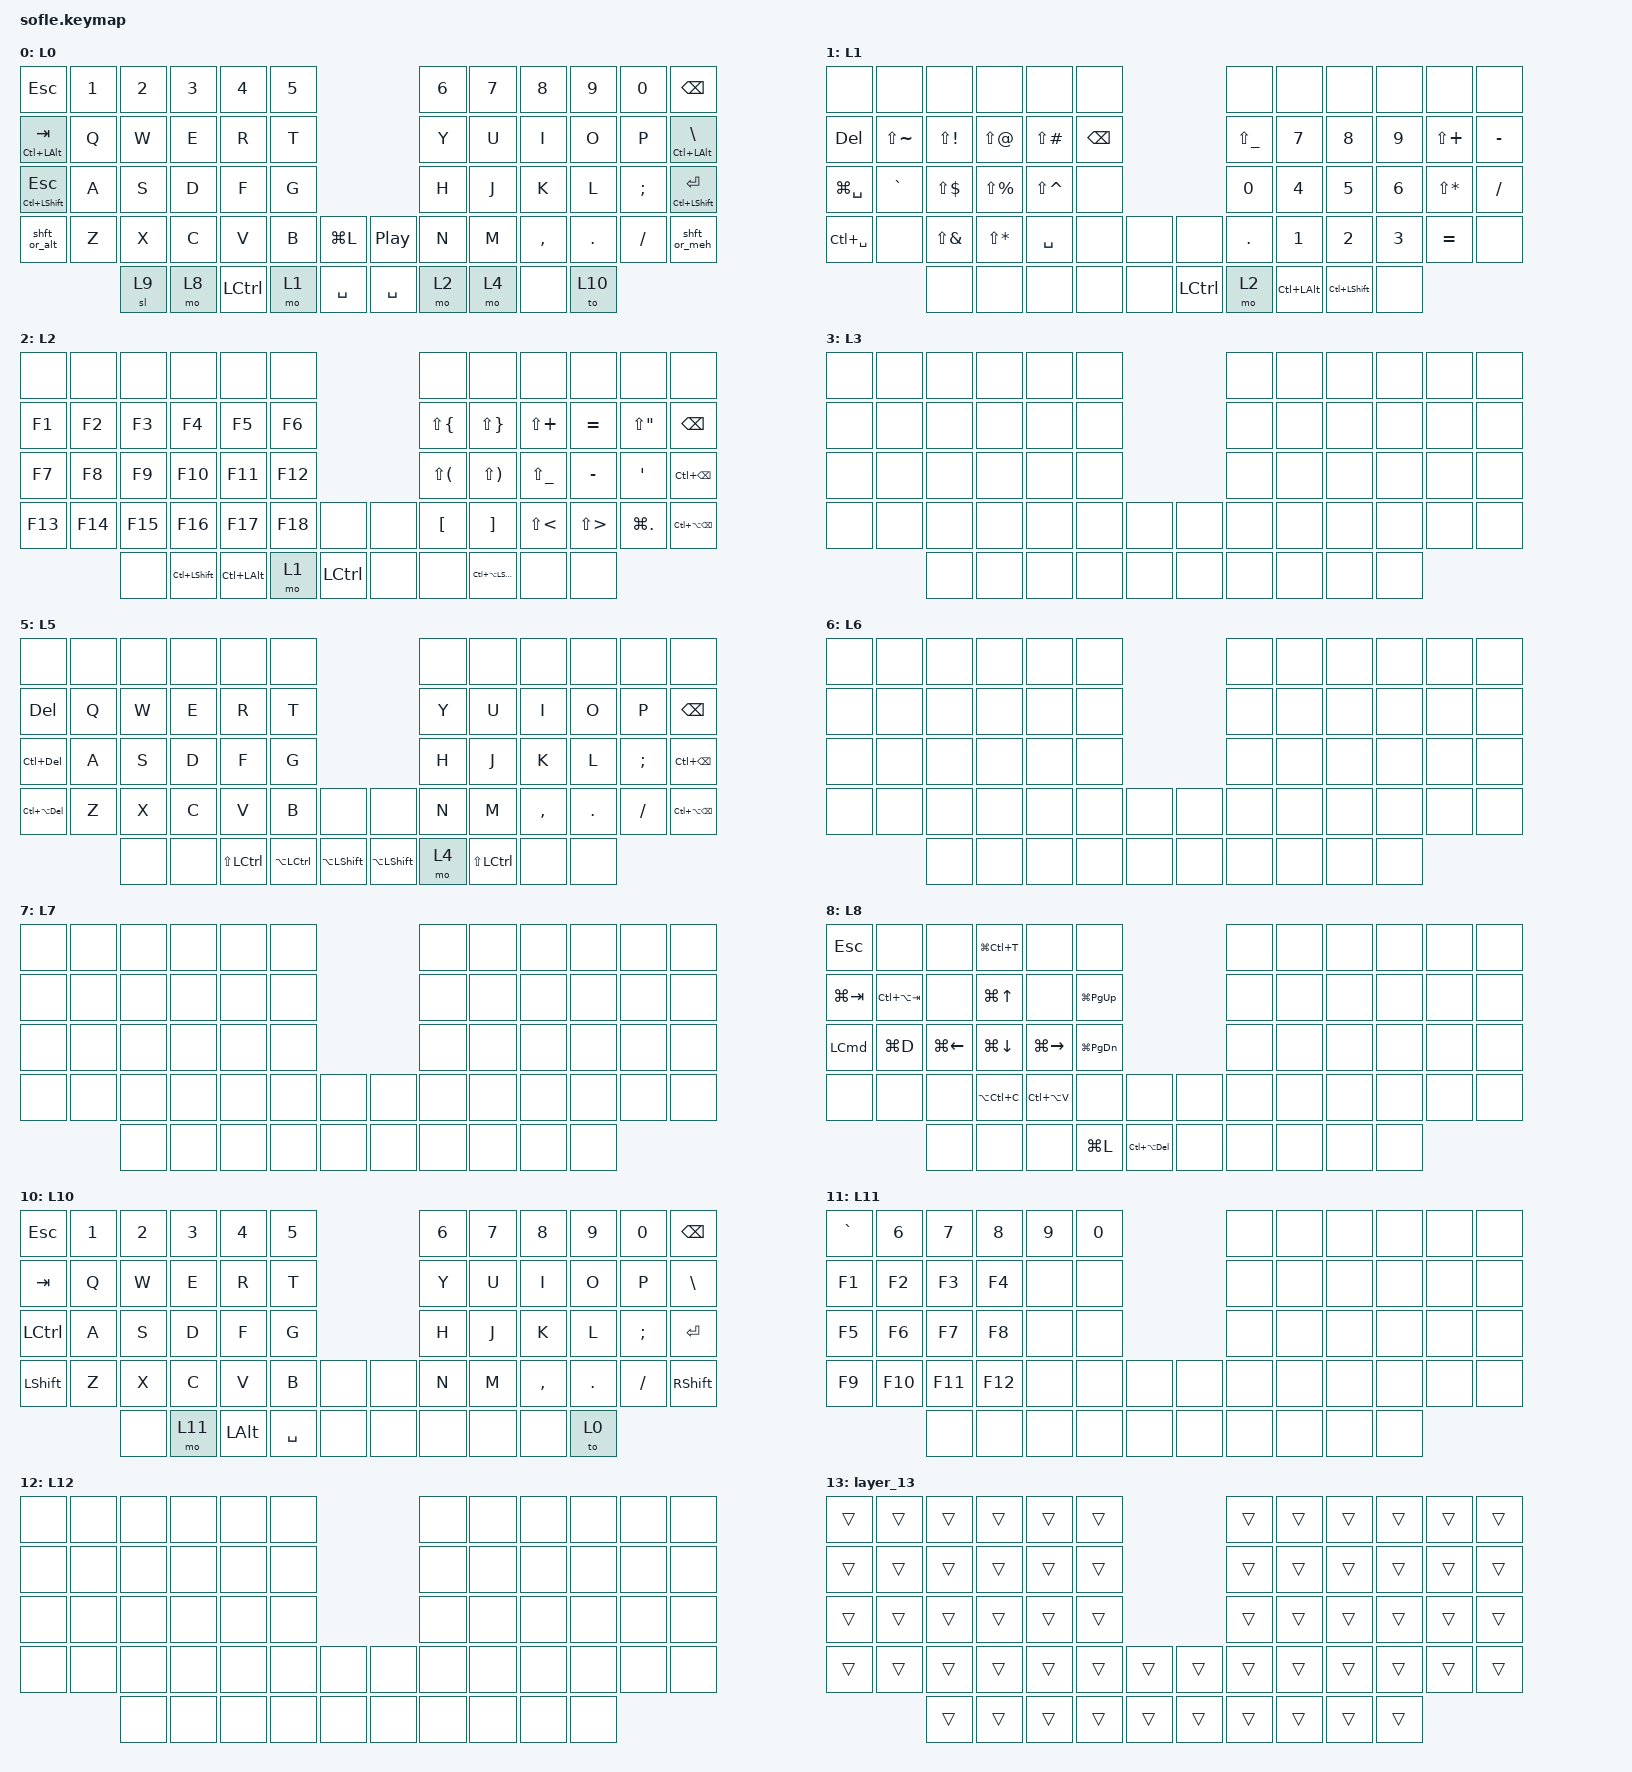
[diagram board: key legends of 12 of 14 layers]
/*
 * Copyright (c) 2020 The ZMK Contributors
 *
 * SPDX-License-Identifier: MIT
 */

#include <behaviors.dtsi>
#include <dt-bindings/zmk/bt.h>
#include <dt-bindings/zmk/ext_power.h>
#include <dt-bindings/zmk/keys.h>
#include <dt-bindings/zmk/outputs.h>

#define L0 0
#define L1 1
#define L2 2
#define L3 3
#define L4 4
#define L5 5
#define L6 6
#define L7 7
#define L8 8
#define L9 9
#define L10 10
#define L11 11
#define L12 12

/ {
    // Activate ADJUST layer by pressing raise and lower

    conditional_layers {
        compatible = "zmk,conditional-layers";

        combined_layer_1 {
            if-layers = <1 2>;
            then-layer = <3>;
        };

        combined_layer_2 {
            if-layers = <4 5>;
            then-layer = <6>;
        };
    };

    behaviors {
        shft_or_alt: shft_or_alt {
            compatible = "zmk,behavior-tap-dance";
            label = "SHFT_OR_ALT";
            #binding-cells = <0>;
            bindings = <&kp LSHFT>, <&kp LEFT_ALT>;
        };
        shft_or_meh: shft_or_meh {
            compatible = "zmk,behavior-tap-dance";
            label = "SHFT_OR_MEH";
            #binding-cells = <0>;
            bindings = <&kp LSHFT>, <&kp LC(LA(LEFT_SHIFT))>;
        };
    };

    keymap {
        compatible = "zmk,keymap";

        L0 {
            bindings = <
&kp ESC                 &kp NUMBER_1  &kp N2  &kp N3  &kp N4     &kp N5                        &kp N6  &kp N7  &kp N8     &kp N9   &kp N0    &kp BACKSPACE
&mt LC(LALT) TAB        &kp Q         &kp W   &kp E   &kp R      &kp T                         &kp Y   &kp U   &kp I      &kp O    &kp P     &mt LC(LEFT_ALT) BACKSLASH
&mt LC(LEFT_SHIFT) ESC  &kp A         &kp S   &kp D   &kp F      &kp G                         &kp H   &kp J   &kp K      &kp L    &kp SEMI  &mt LC(LSHFT) ENTER
&shft_or_alt            &kp Z         &kp X   &kp C   &kp V      &kp B   &kp LG(L)  &kp C_PP   &kp N   &kp M   &kp COMMA  &kp DOT  &kp FSLH  &shft_or_meh
                                      &sl 9   &mo 8   &kp LCTRL  &mo 1   &kp SPACE  &kp SPACE  &mo 2   &mo 4   &none      &to 10
            >;

            sensor-bindings =
                <&inc_dec_kp C_VOL_UP C_VOL_DN>,
                <&inc_dec_kp C_NEXT C_PREV>;
        };

        L1 {
            bindings = <
&none          &none          &none         &none          &none          &none                       &none          &none             &none               &none   &none         &none
&kp DEL        &kp LS(TILDE)  &kp LS(EXCL)  &kp LS(AT)     &kp LS(POUND)  &kp BSPC                    &kp LS(UNDER)  &kp N7            &kp N8              &kp N9  &kp LS(PLUS)  &kp MINUS
&kp LG(SPACE)  &kp GRAVE      &kp LS(DLLR)  &kp LS(PRCNT)  &kp LS(CARET)  &none                       &kp N0         &kp N4            &kp N5              &kp N6  &kp LS(STAR)  &kp FSLH
&kp LC(SPACE)  &none          &kp LS(AMPS)  &kp LS(STAR)   &kp SPACE      &none     &none  &none      &kp DOT        &kp N1            &kp N2              &kp N3  &kp EQUAL     &none
                              &none         &none          &none          &none     &none  &kp LCTRL  &mo 2          &kp LC(LEFT_ALT)  &kp LC(LEFT_SHIFT)  &none
            >;
        };

        L2 {
            bindings = <
&none    &none    &none    &none               &none             &none                      &none         &none                   &none          &none       &none           &none
&kp F1   &kp F2   &kp F3   &kp F4              &kp F5            &kp F6                     &kp LS(LBRC)  &kp LS(RBRC)            &kp LS(PLUS)   &kp EQUAL   &kp LS(DQT)     &kp BSPC
&kp F7   &kp F8   &kp F9   &kp F10             &kp F11           &kp F12                    &kp LS(LPAR)  &kp LS(RPAR)            &kp LS(UNDER)  &kp MINUS   &kp SQT         &kp LC(BSPC)
&kp F13  &kp F14  &kp F15  &kp F16             &kp F17           &kp F18  &none      &none  &kp LBKT      &kp RBKT                &kp LS(LT)     &kp LS(GT)  &kp LG(PERIOD)  &kp LC(LA(BSPC))
                  &none    &kp LC(LEFT_SHIFT)  &kp LC(LEFT_ALT)  &mo 1    &kp LCTRL  &none  &none         &kp LC(LA(LEFT_SHIFT))  &none          &none
            >;
        };

        L3 {
            bindings = <
&none  &none  &none  &none  &none  &none                &none  &none  &none  &none  &none  &none
&none  &none  &none  &none  &none  &none                &none  &none  &none  &none  &none  &none
&none  &none  &none  &none  &none  &none                &none  &none  &none  &none  &none  &none
&none  &none  &none  &none  &none  &none  &none  &none  &none  &none  &none  &none  &none  &none
              &none  &none  &none  &none  &none  &none  &none  &none  &none  &none
            >;
        };

        L4 {
            bindings = <
&none         &none     &none             &none               &none              &none                    &none              &none              &none               &none               &none                  &none
&kp LC(HOME)  &kp HOME  &kp LC(LEFT)      &kp UP              &kp LC(RIGHT)      &kp PG_UP                &kp LS(LC(LA(Y)))  &kp LS(LC(LA(U)))  &kp LS(LC(LA(I)))   &kp LS(LC(LA(O)))   &kp LS(LC(LA(P)))      &kp LS(LC(LA(PIPE)))
&kp LC(END)   &kp END   &kp LEFT          &kp DOWN            &kp RIGHT          &kp PG_DN                &kp LS(LC(LA(H)))  &kp LS(LC(LA(J)))  &kp LS(LC(LA(K)))   &kp LS(LC(LA(L)))   &kp LS(LC(LA(COLON)))  &none
&none         &none     &kp LC(LA(LEFT))  &none               &kp LC(LA(RIGHT))  &none      &none  &none  &kp LS(LC(LA(N)))  &kp LS(LC(LA(M)))  &kp LS(LC(LA(LT)))  &kp LS(LC(LA(GT)))  &kp LS(LC(LA(QMARK)))  &none
                        &none             &kp LC(LEFT_SHIFT)  &kp LEFT_ALT       &kp LSHFT  &none  &none  &none              &none              &none               &none
            >;
        };

        L5 {
            bindings = <
&none            &none  &none  &none  &none          &none                                        &none  &none          &none      &none    &none     &none
&kp DEL          &kp Q  &kp W  &kp E  &kp R          &kp T                                        &kp Y  &kp U          &kp I      &kp O    &kp P     &kp BSPC
&kp LC(DEL)      &kp A  &kp S  &kp D  &kp F          &kp G                                        &kp H  &kp J          &kp K      &kp L    &kp SEMI  &kp LC(BSPC)
&kp LC(LA(DEL))  &kp Z  &kp X  &kp C  &kp V          &kp B          &none          &none          &kp N  &kp M          &kp COMMA  &kp DOT  &kp FSLH  &kp LC(LA(BSPC))
                        &none  &none  &kp LS(LCTRL)  &kp LA(LCTRL)  &kp LA(LSHFT)  &kp LA(LSHFT)  &mo 4  &kp LS(LCTRL)  &none      &none
            >;
        };

        L6 {
            bindings = <
&none  &none  &none  &none  &none  &none                &none  &none  &none  &none  &none  &none
&none  &none  &none  &none  &none  &none                &none  &none  &none  &none  &none  &none
&none  &none  &none  &none  &none  &none                &none  &none  &none  &none  &none  &none
&none  &none  &none  &none  &none  &none  &none  &none  &none  &none  &none  &none  &none  &none
              &none  &none  &none  &none  &none  &none  &none  &none  &none  &none
            >;
        };

        L7 {
            bindings = <
&none  &none  &none  &none  &none  &none                &none  &none  &none  &none  &none  &none
&none  &none  &none  &none  &none  &none                &none  &none  &none  &none  &none  &none
&none  &none  &none  &none  &none  &none                &none  &none  &none  &none  &none  &none
&none  &none  &none  &none  &none  &none  &none  &none  &none  &none  &none  &none  &none  &none
              &none  &none  &none  &none  &none  &none  &none  &none  &none  &none
            >;
        };

        L8 {
            bindings = <
&kp ESC      &none            &none               &kp LG(LC(T))  &none          &none                                  &none  &none  &none  &none  &none  &none
&kp LG(TAB)  &kp LC(LA(TAB))  &none               &kp LG(UP)     &none          &kp LG(PG_UP)                          &none  &none  &none  &none  &none  &none
&kp LCMD     &kp LG(D)        &kp LG(LEFT_ARROW)  &kp LG(DOWN)   &kp LG(RIGHT)  &kp LG(PG_DN)                          &none  &none  &none  &none  &none  &none
&none        &none            &none               &kp LA(LC(C))  &kp LC(LA(V))  &none          &none            &none  &none  &none  &none  &none  &none  &none
                              &none               &none          &none          &kp LG(L)      &kp LC(LA(DEL))  &none  &none  &none  &none  &none
            >;
        };

        L9 {
            bindings = <
&kp ESC              &none                &none                &none                &none                &none                              &none  &none  &none  &none         &none         &ext_power EP_TOG
&kp LS(LA(LC(F1)))   &kp LS(LA(LC(F2)))   &kp LS(LA(LC(F3)))   &kp LS(LA(LC(F4)))   &kp LS(LA(LC(F5)))   &kp LS(LA(LC(F6)))                 &none  &none  &none  &none         &none         &bt BT_CLR
&kp LS(LA(LC(F7)))   &kp LS(LA(LC(F8)))   &kp LS(LA(LC(F9)))   &kp LS(LA(LC(F10)))  &kp LS(LA(LC(F11)))  &kp LS(LA(LC(F12)))                &none  &none  &none  &none         &out OUT_USB  &out OUT_BLE
&kp LS(LA(LC(F13)))  &kp LS(LA(LC(F14)))  &kp LS(LA(LC(F15)))  &kp LS(LA(LC(F16)))  &kp LS(LA(LC(F17)))  &kp LS(LA(LC(F18)))  &none  &none  &none  &none  &none  &bt BT_SEL 0  &bt BT_SEL 1  &bt BT_SEL 2
                                          &none                &none                &none                &none                &none  &none  &none  &none  &none  &to 10
            >;
        };

        L10 {
            bindings = <
&kp ESC    &kp N1  &kp N2  &kp N3  &kp N4        &kp N5                   &kp N6  &kp N7  &kp N8     &kp N9   &kp N0    &kp BSPC
&kp TAB    &kp Q   &kp W   &kp E   &kp R         &kp T                    &kp Y   &kp U   &kp I      &kp O    &kp P     &kp BSLH
&kp LCTRL  &kp A   &kp S   &kp D   &kp F         &kp G                    &kp H   &kp J   &kp K      &kp L    &kp SEMI  &kp RET
&kp LSHFT  &kp Z   &kp X   &kp C   &kp V         &kp B      &none  &none  &kp N   &kp M   &kp COMMA  &kp DOT  &kp FSLH  &kp RSHFT
                   &none   &mo 11  &kp LEFT_ALT  &kp SPACE  &none  &none  &none   &none   &none      &to 0
            >;
        };

        L11 {
            bindings = <
&kp GRAVE  &kp N6   &kp N7   &kp N8   &kp N9  &kp N0                &none  &none  &none  &none  &none  &none
&kp F1     &kp F2   &kp F3   &kp F4   &none   &none                 &none  &none  &none  &none  &none  &none
&kp F5     &kp F6   &kp F7   &kp F8   &none   &none                 &none  &none  &none  &none  &none  &none
&kp F9     &kp F10  &kp F11  &kp F12  &none   &none   &none  &none  &none  &none  &none  &none  &none  &none
                    &none    &none    &none   &none   &none  &none  &none  &none  &none  &none
            >;
        };

        L12 {
            bindings = <
&none  &none  &none  &none  &none  &none                &none  &none  &none  &none  &none  &none
&none  &none  &none  &none  &none  &none                &none  &none  &none  &none  &none  &none
&none  &none  &none  &none  &none  &none                &none  &none  &none  &none  &none  &none
&none  &none  &none  &none  &none  &none  &none  &none  &none  &none  &none  &none  &none  &none
              &none  &none  &none  &none  &none  &none  &none  &none  &none  &none
            >;
        };

        layer_13 {
            bindings = <
&trans  &trans  &trans  &trans  &trans  &trans                  &trans  &trans  &trans  &trans  &trans  &trans
&trans  &trans  &trans  &trans  &trans  &trans                  &trans  &trans  &trans  &trans  &trans  &trans
&trans  &trans  &trans  &trans  &trans  &trans                  &trans  &trans  &trans  &trans  &trans  &trans
&trans  &trans  &trans  &trans  &trans  &trans  &trans  &trans  &trans  &trans  &trans  &trans  &trans  &trans
                &trans  &trans  &trans  &trans  &trans  &trans  &trans  &trans  &trans  &trans
            >;
        };
    };
};
